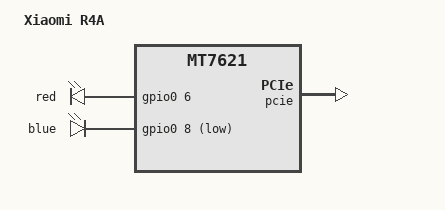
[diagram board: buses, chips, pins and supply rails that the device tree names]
/dts-v1/;

#include "mt7621.dtsi"
#include <dt-bindings/input/input.h>
#include "mt7621-spi-16m-layout.dtsi"
#include "mt7621-raeth-gmac2.dtsi"
#include "mt7621-pinctrl-default-gpio.dtsi"

/ {
	compatible = "mediatek,mt7621-soc";
	model = "Xiaomi R4A";

	chosen {
		bootargs = "console=ttyS0,57600";
	};

	leds {
		compatible = "gpio-leds";

		stat_r {
			label = "red";
			gpios = <&gpio0 6 GPIO_ACTIVE_HIGH>;
		};

		stat_b {
			label = "blue";
			gpios = <&gpio0 8 GPIO_ACTIVE_LOW>;
		};
	};

};

&pcie {
	status = "okay";
};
